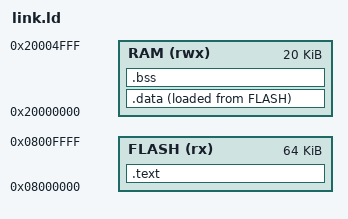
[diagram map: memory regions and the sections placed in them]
/* STM32F103C8T6: 64K flash, 20K RAM */
MEMORY
{
  FLASH (rx)  : ORIGIN = 0x08000000, LENGTH = 64K
  RAM   (rwx) : ORIGIN = 0x20000000, LENGTH = 20K
}

ENTRY(Reset_Handler)

/* top of RAM = initial stack pointer */
_estack = ORIGIN(RAM) + LENGTH(RAM);

SECTIONS
{
  .text :
  {
    KEEP(*(.isr_vector))
    *(.text*)
    *(.rodata*)
  } > FLASH

  _sidata = LOADADDR(.data);

  .data :
  {
    _sdata = .;
    *(.data*)
    _edata = .;
  } > RAM AT> FLASH

  .bss :
  {
    _sbss = .;
    *(.bss*)
    *(COMMON)
    _ebss = .;
  } > RAM

  /DISCARD/ : { *(.ARM.exidx*) *(.comment) }
}
